VERSION ""

NS_ :

BS_:

BU_: DummyECU

BO_ 768 EngineData: 8 DummyECU
 SG_ Temperature : 7|16@0+ (0.1,0) [0|6553.5] "degC" Vector__XXX
 SG_ Pressure : 23|16@0+ (0.01,0) [0|655.35] "bar" Vector__XXX

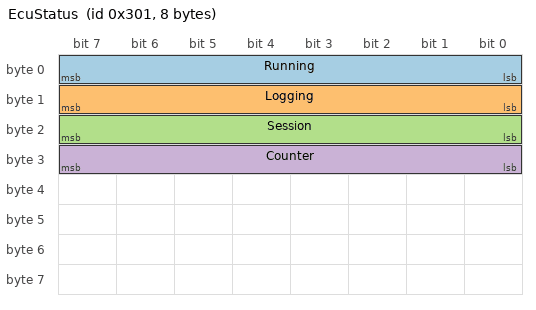
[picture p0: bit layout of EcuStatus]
BO_ 769 EcuStatus: 8 DummyECU
 SG_ Running : 0|8@1+ (1,0) [0|1] "" Vector__XXX
 SG_ Logging : 8|8@1+ (1,0) [0|1] "" Vector__XXX
 SG_ Session : 16|8@1+ (1,0) [1|3] "" Vector__XXX
 SG_ Counter : 24|8@1+ (1,0) [0|255] "" Vector__XXX

CM_ BO_ 768 "Broadcast every 100 ms by dummy_ecu.py; temperature rises while running";
CM_ BO_ 769 "Broadcast every 100 ms by dummy_ecu.py";
VAL_ 769 Session 1 "default" 2 "programming" 3 "extended" ;
